# ESP32-C2 register map
Vendor: ESPRESSIF SYSTEMS (SHANGHAI) CO., LTD.; Series: ESP32 C-Series; File version: 11
CPU: RV32IMC r0p0, little endian, no MPU, no FPU, 0 interrupt priority bits
Address unit: 32 bits
Registers are 32-bit, read-write, reset 0x0 unless marked. A register's access mark holds for its fields unless they carry their own. Offsets are from the block's base; [hi:lo] are bit positions; {n}, {i} and the like mark numbered series.

## MMU_TABLE — External memory cache MMU table
Base 0x600C5000
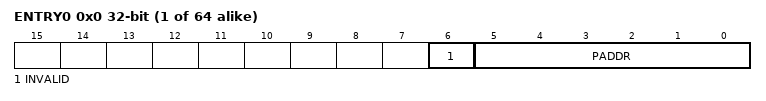
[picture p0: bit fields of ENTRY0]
{0x0+4i} ENTRY{i} (i=0..63) — MMU table entry
  [6] INVALID — Set to mark this entry invalid
  [5:0] PADDR — Physical page number

## INTERRUPT_CORE0 — Interrupt Controller (Core 0)
Base 0x600C2000
{0x0+4i} CORE_0_INTR_MAP{i} (i=0..41)
  [4:0] MAP
0xAC CORE_0_INTR_STATUS{x} (x=REG_0,REG_1; step 0x4) ro — register description
  [31:0] INTR_STATUS_0 — Need add description
0xB4 CLOCK_GATE reset 0x1 — register description
  [0] REG_CLK_EN — Need add description
0xB8 CPU_INT_ENABLE — register description
  [31:0] CPU_INT_ENABLE — Need add description
0xBC CPU_INT_TYPE — register description
  [31:0] CPU_INT_TYPE — Need add description
0xC0 CPU_INT_CLEAR — register description
  [31:0] CPU_INT_CLEAR — Need add description
0xC4 CPU_INT_EIP_STATUS ro — register description
  [31:0] CPU_INT_EIP_STATUS — Need add description
{0xC8+4i} CPU_INT_PRI{i} (i=0..31) — register description
  [3:0] MAP — Need add description
0x148 CPU_INT_THRESH — register description
  [3:0] CPU_INT_THRESH — Need add description
0x7FC INTERRUPT_REG_DATE — register description

## IO_MUX — Input/Output Multiplexer
Base 0x60009000
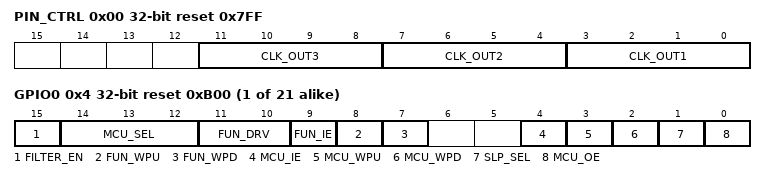
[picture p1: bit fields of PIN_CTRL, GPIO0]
0x00 PIN_CTRL reset 0x7FF — Clock Output Configuration Register
  [11:8] CLK_OUT3 — If you want to output clock for I2S to CLK_OUT_out3, set this register to 0x0. CLK_OUT_out3 can be found in peripheral output signals.
  [7:4] CLK_OUT2 — If you want to output clock for I2S to CLK_OUT_out2, set this register to 0x0. CLK_OUT_out2 can be found in peripheral output signals.
  [3:0] CLK_OUT1 — If you want to output clock for I2S to CLK_OUT_out1, set this register to 0x0. CLK_OUT_out1 can be found in peripheral output signals.
{0x4+4i} GPIO{i} (i=0..20) reset 0xB00 — IO MUX Configure Register for pad XTAL_32K_P
  [15] FILTER_EN — Enable filter for pin input signals. 1: Filter enabled; 2: Filter disabled.
  [14:12] MCU_SEL — Select IO MUX function for this signal. 0: Select Function 1; 1: Select Function 2; etc.
  [11:10] FUN_DRV — Select the drive strength of the pad. 0: ~5 mA; 1: ~10mA; 2: ~20mA; 3: ~40mA.
  [9] FUN_IE — Input enable of the pad. 1: input enabled; 0: input disabled.
  [8] FUN_WPU — Pull-up enable of the pad. 1: internal pull-up enabled; 0: internal pull-up disabled.
  [7] FUN_WPD — Pull-down enable of the pad. 1: internal pull-down enabled; 0: internal pull-down disabled.
  [4] MCU_IE — Input enable of the pad during sleep mode. 1: input enabled; 0: input disabled.
  [3] MCU_WPU — Pull-up enable of the pad during sleep mode. 1: internal pull-up enabled; 0: internal pull-up disabled.
  [2] MCU_WPD — Pull-down enable of the pad in sleep mode. 1: internal pull-down enabled; 0: internal pull-down disabled.
  [1] SLP_SEL — Sleep mode selection of this pad. Set to 1 to put the pad in pad mode.
  [0] MCU_OE — Output enable of the pad in sleep mode. 1: output enabled; 0: output disabled.
0xFC DATE — IO MUX Version Control Register

## MODEM_CLKRST — MODEM_CLKRST Peripheral
Base 0x6004D800
0x00 CLK_CONF
  [0] CLK_EN
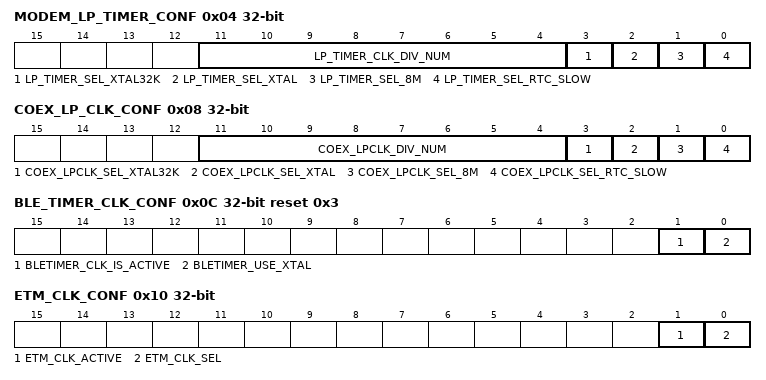
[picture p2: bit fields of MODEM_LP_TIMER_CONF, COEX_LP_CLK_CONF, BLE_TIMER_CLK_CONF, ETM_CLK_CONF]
0x04 MODEM_LP_TIMER_CONF
  [11:4] LP_TIMER_CLK_DIV_NUM, [3] LP_TIMER_SEL_XTAL32K, [2] LP_TIMER_SEL_XTAL, [1] LP_TIMER_SEL_8M, [0] LP_TIMER_SEL_RTC_SLOW
0x08 COEX_LP_CLK_CONF
  [11:4] COEX_LPCLK_DIV_NUM, [3] COEX_LPCLK_SEL_XTAL32K, [2] COEX_LPCLK_SEL_XTAL, [1] COEX_LPCLK_SEL_8M, [0] COEX_LPCLK_SEL_RTC_SLOW
0x0C BLE_TIMER_CLK_CONF reset 0x3
  [1] BLETIMER_CLK_IS_ACTIVE, [0] BLETIMER_USE_XTAL
0x0C DATE — APB_CTRL_DATE_REG
0x10 ETM_CLK_CONF
  [1] ETM_CLK_ACTIVE, [0] ETM_CLK_SEL
